# GD32H77x_78x register map
File version: 1.0
CPU: CM7 r1p2, little endian, MPU, FPU, 4 interrupt priority bits
Registers are 32-bit, read-write, reset 0x0 unless marked. A register's access mark holds for its fields unless they carry their own. Offsets are from the block's base; [hi:lo] are bit positions; {n}, {i} and the like mark numbered series; 'fields as' and 'values as' point back to an identical list.

## NVIC — Nested Vectored Interrupt Controller
Base 0xE000E100
{0x0+4i} ISER{i} (i=0..2) — Interrupt Set-Enable Register
  [31:0] SETENA
0x0C ISER3 — Interrupt Set-Enable Register
{0x80+4i} ICER{i} (i=0..2) — Interrupt Clear-Enable Register
  [31:0] CLRENA
0x8C ICER3 — Interrupt Clear-Enable Register
{0x100+4i} ISPR{i} (i=0..2) — Interrupt Set-Pending Register
  [31:0] SETPEND
0x10C ISPR3 — Interrupt Set-Pending Register
{0x180+4i} ICPR{i} (i=0..2) — Interrupt Clear-Pending Register
  [31:0] CLRPEND
0x1C0 ICPR3 — Interrupt Clear-Pending Register
{0x200+4i} IABR{i} ro (i=0..2) — Interrupt Active Bit Register
  [31:0] ACTIVE
0x20C IABR3 — Interrupt Active Bit Register
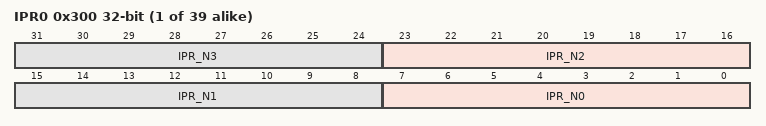
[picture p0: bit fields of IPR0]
{0x300+4i} IPR{i} (i=0..38) — Interrupt Priority Register
  [8n+7:8n] IPR_N{n} (n=0..3)

## OSPIM — OSPI I/O Manager
Base 0x5200B400
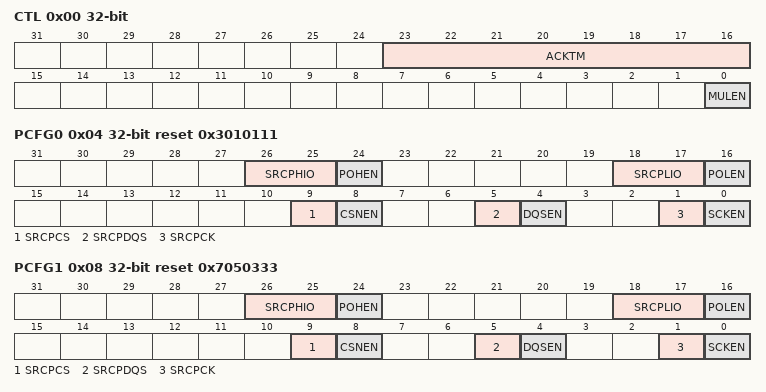
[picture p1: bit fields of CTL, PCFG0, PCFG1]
0x00 CTL — 2Control register
  [23:16] ACKTM — REQ to ACK time
  [0] MULEN — Multiplexed mode enable
0x04 PCFG0 reset 0x3010111 — Port configuration regist 0
  [26:25] SRCPHIO — Source selection for IO[7:4] of port x
  [24] POHEN — Enable for IO[7:4] of port x
  [18:17] SRCPLIO — Source selection for IO[3:0] of port x
  [16] POLEN — Enable for IO[3:0] of port x
  [9] SRCPCS — Source selection for CSN of port x
  [8] CSNEN — Enable for CSN of port x
  [5] SRCPDQS — ource selection for DQS of port n
  [4] DQSEN — Enable for DQS of port x
  [1] SRCPCK — Source selection for SCK of port x
  [0] SCKEN — Enable for SCK of port x
0x08 PCFG1 reset 0x7050333 — Port configuration regist 1
  fields as PCFG0

## PKCAU — Public Key Cryptographic Acceleration Unit
Base 0x48000000
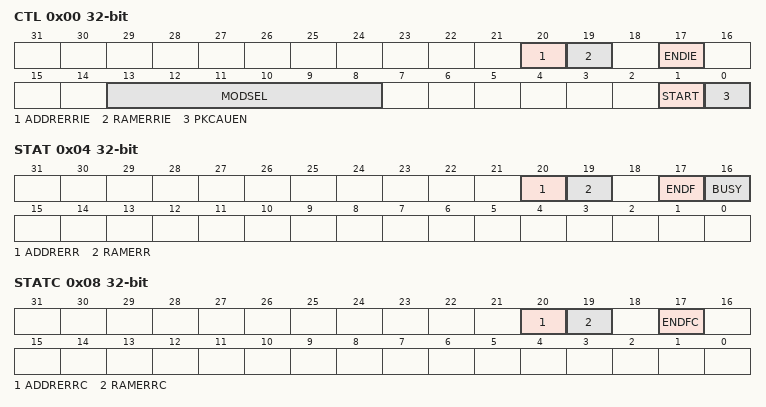
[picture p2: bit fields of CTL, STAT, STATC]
0x00 CTL — Control register
  [20] ADDRERRIE — Address error interrupt enable
  [19] RAMERRIE — RAM error interrupt enable
  [17] ENDIE — End of operation interrupt enable
  [13:8] MODSEL — PKCAU operation mode selection
  [1] START — PKCAU starts operation
  [0] PKCAUEN — PKCAU enable
0x04 STAT ro — Status register
  [20] ADDRERR — Address error.
  [19] RAMERR — PKCAU RAM error
  [17] ENDF — End of PKCAU operation
  [16] BUSY — Busy flag
0x08 STATC wo — Status clear register
  [20] ADDRERRC — Address error flag clear.
  [19] RAMERRC — PKCAU RAM error flag clear.
  [17] ENDFC — End of PKCAU operation flag clear.

## RAMECCMU0 — RAM ECC monitor unit0
Base 0x52009000
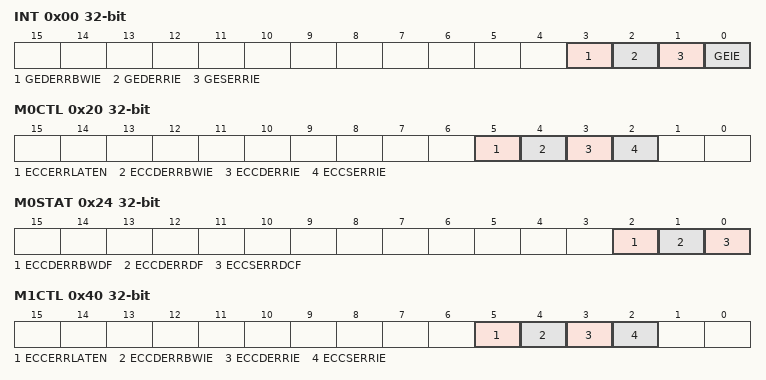
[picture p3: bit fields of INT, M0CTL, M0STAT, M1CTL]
0x00 INT — RAMECCMU global interruput register
  [3] GEDERRBWIE — Global ECC double error on byte write interrupt enable
  [2] GEDERRIE — Global ECC double error interrupt enable
  [1] GESERRIE — Global ECC single error interrupt enable
  [0] GEIE — Global ECC interrupt enable
0x20 M0CTL — monitor 0 control register
  [5] ECCERRLATEN — ECC error latching enable
  [4] ECCDERRBWIE — ECC double error on byte write interrupt enable
  [3] ECCDERRIE — ECC double error interrupt enable
  [2] ECCSERRIE — ECC single error interrupt enable
0x24 M0STAT — monitor 0 status register
  [2] ECCDERRBWDF — ECC double error on byte write detected flag
  [1] ECCDERRDF — ECC double error detected flag
  [0] ECCSERRDCF — ECC single error detected and corrected flag
0x28 M0FADDR ro — monitor 0 failing address register
  [31:0] ECCFADDR — ECC error failing address
0x2C M0FDL ro — monitor 0 failing data low register
  [31:0] ECCFDL — ECC failing data low bits
{0x30+0x20*i} M{i}FDH ro (i=0..4) — monitor 0 failing data high register
  [31:0] ECCFDH — ECC failing data high bitss
0x34 M0FECODE ro — monitor 0 failing ECC error code register
  [31:0] ECCFECODE — ECC failing error code
0x40 M1CTL — monitor 1 control register
  fields as M0CTL
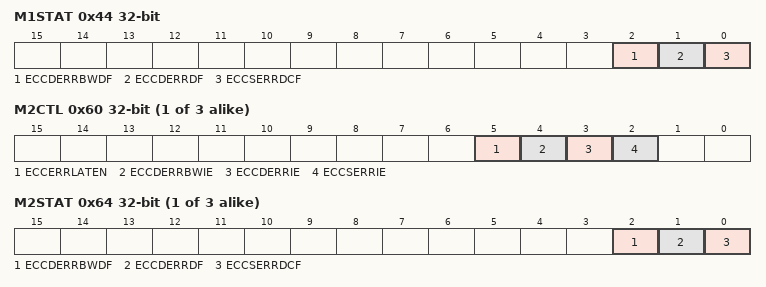
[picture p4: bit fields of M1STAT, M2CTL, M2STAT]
0x44 M1STAT — monitor 1 status register
  fields as M0STAT
0x48 M1FADDR ro — monitor 1 failing address register
  [31:0] ECCFADDR — ECC error failing address
0x4C M1FDL ro — monitor 1 failing data low register
  [31:0] ECCFDL — ECC failing data low bits
0x54 M1FECODE ro — monitor 1 failing ECC error code register
  [31:0] ECCFECODE — ECC failing error code
{0x20+0x20*i} M{i}CTL (i=2..4) — monitor 0 control register
  fields as M0CTL
{0x24+0x20*i} M{i}STAT (i=2..4) — monitor 0 status register
  fields as M0STAT
{0x28+0x20*i} M{i}FADDR ro (i=2..4) — monitor 0 failing address register
  [31:0] ECCFADDR — ECC error failing address
{0x2C+0x20*i} M{i}FDL ro (i=2..4) — monitor 0 failing data low register
  [31:0] ECCFDL — ECC failing data low bits
{0x34+0x20*i} M{i}FECODE ro (i=2..4) — monitor 0 failing ECC error code register
  [31:0] ECCFECODE — ECC failing error code

## RAMECCMU1 — RAM ECC monitor unit 1
Base 0x48023000
Registers as RAMECCMU0, without M3CTL, M3STAT, M3FADDR, M3FDL, M3FDH, M3FECODE, M4CTL, M4STAT, M4FADDR, M4FDL, M4FDH, M4FECODE.
